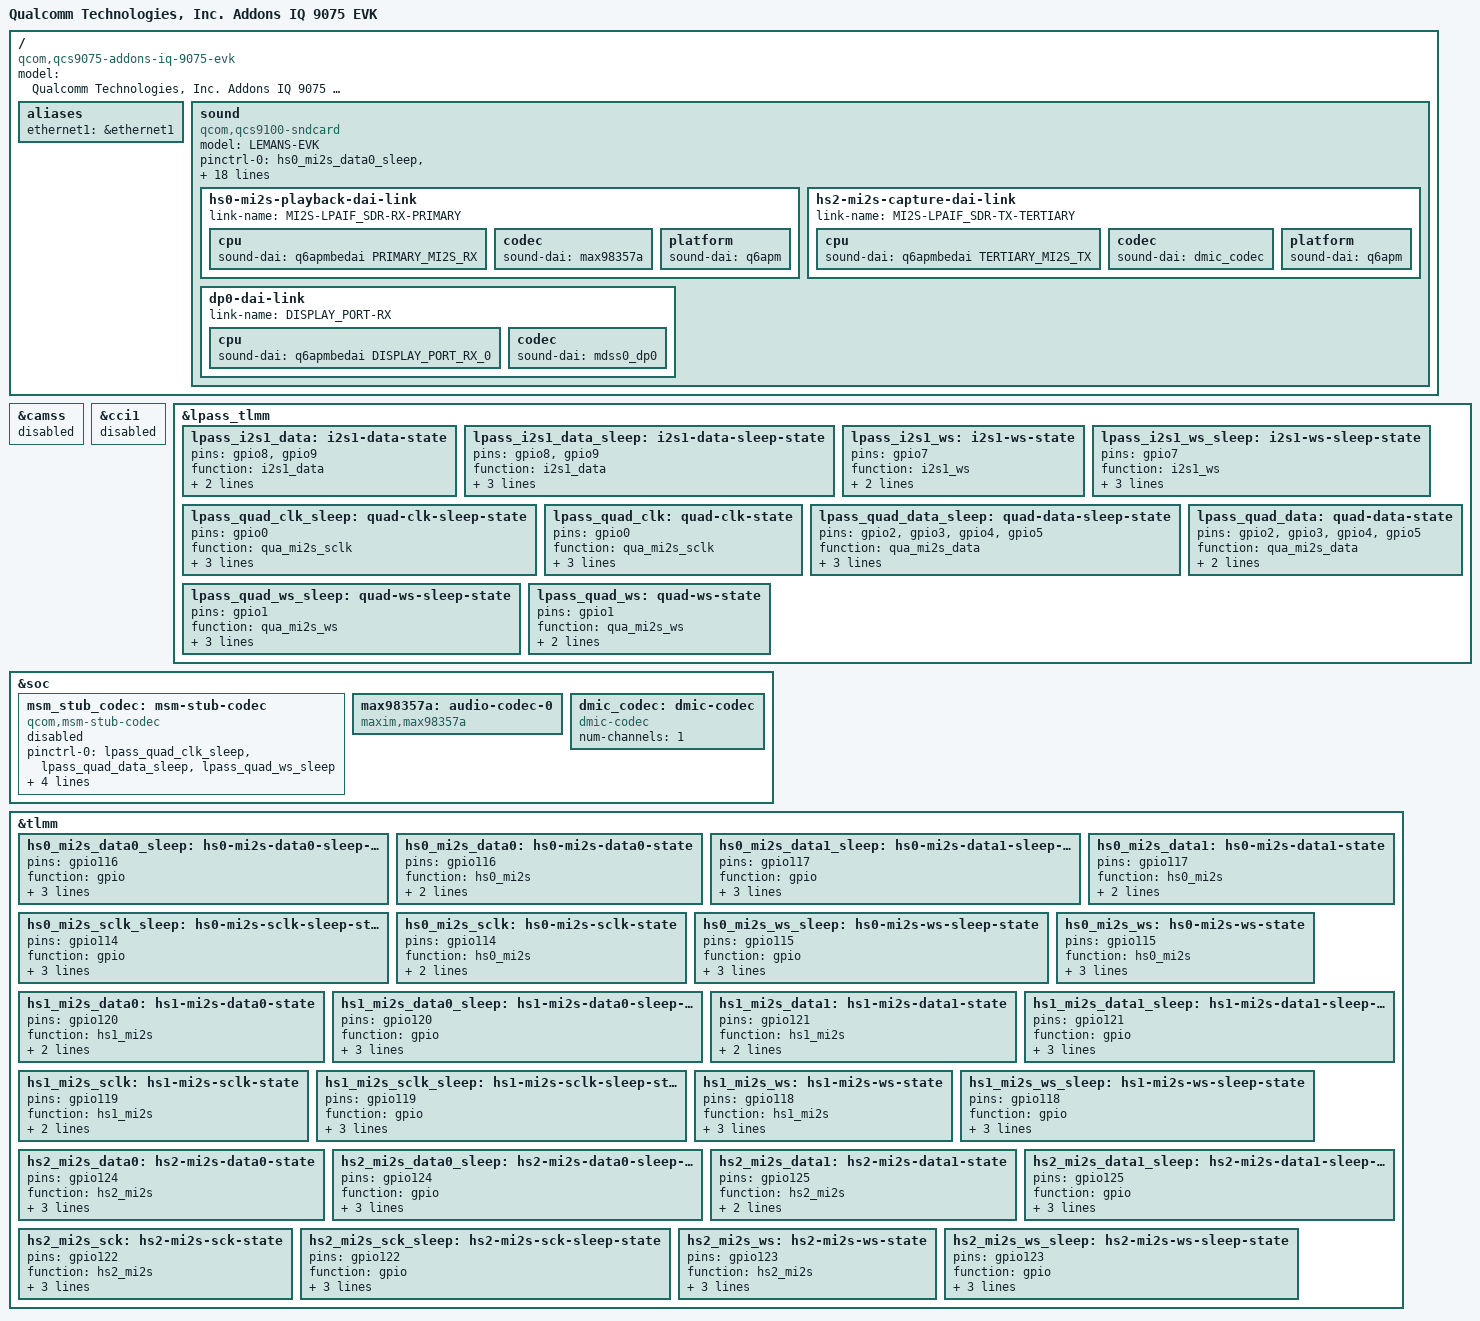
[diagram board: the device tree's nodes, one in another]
// SPDX-License-Identifier: BSD-3-Clause
/*
 * Copyright (c) 2024-2025, Qualcomm Innovation Center, Inc. All rights reserved.
 * Copyright (c) Qualcomm Technologies, Inc. and/or its subsidiaries.
 */
/dts-v1/;

#include "qcs9075-iq-9075-evk.dts"
#include "sa8775p-addons.dtsi"

/ {
	model = "Qualcomm Technologies, Inc. Addons IQ 9075 EVK";
	compatible = "qcom,qcs9075-addons-iq-9075-evk", "qcom,qcs9075", "qcom,sa8775p";

	aliases {
		ethernet1 = &ethernet1;
	};

	sound {
		compatible = "qcom,qcs9100-sndcard";
		model = "LEMANS-EVK";

		pinctrl-0 = <&hs0_mi2s_data0_sleep>,<&hs0_mi2s_data1_sleep>,<&hs0_mi2s_sclk_sleep>,
			    <&hs0_mi2s_ws_sleep>,<&hs1_mi2s_data0_sleep>,<&hs1_mi2s_data1_sleep>,
			    <&hs1_mi2s_sclk_sleep>,<&hs1_mi2s_ws_sleep>,<&hs2_mi2s_data0_sleep>,
			    <&hs2_mi2s_data1_sleep>, <&hs2_mi2s_sck_sleep>, <&hs2_mi2s_ws_sleep>;
		pinctrl-1 = <&hs1_mi2s_data0>, <&hs0_mi2s_data0>,
			    <&hs0_mi2s_sclk>, <&hs0_mi2s_data1>, <&hs0_mi2s_ws>,
			    <&hs1_mi2s_sclk>, <&hs1_mi2s_data1>, <&hs1_mi2s_ws>,
			    <&hs2_mi2s_data0>, <&hs2_mi2s_data1>, <&hs2_mi2s_sck>,
			    <&hs2_mi2s_ws>;
		pinctrl-2 = <&hs0_mi2s_data0_sleep>,<&hs0_mi2s_data1_sleep>,<&hs0_mi2s_sclk_sleep>,
                            <&hs0_mi2s_ws_sleep>,<&hs1_mi2s_data0_sleep>,<&hs1_mi2s_data1_sleep>,
                            <&hs1_mi2s_sclk_sleep>,<&hs1_mi2s_ws_sleep>,<&hs2_mi2s_data0_sleep>,
                            <&hs2_mi2s_data1_sleep>, <&hs2_mi2s_sck_sleep>, <&hs2_mi2s_ws_sleep>;

		pinctrl-names = "default", "mi2s_active", "mi2s_sleep";

		hs0-mi2s-playback-dai-link {
			link-name = "MI2S-LPAIF_SDR-RX-PRIMARY";

			cpu {
				sound-dai = <&q6apmbedai PRIMARY_MI2S_RX>;
			};

			codec {
				sound-dai = <&max98357a>;
			};

			platform {
				sound-dai = <&q6apm>;
			};
		};

		hs2-mi2s-capture-dai-link {
			link-name = "MI2S-LPAIF_SDR-TX-TERTIARY";

			cpu {
				sound-dai = <&q6apmbedai TERTIARY_MI2S_TX>;
			};

			codec {
				sound-dai = <&dmic_codec>;
			};

			platform {
				sound-dai = <&q6apm>;
			};
		};

		dp0-dai-link {
			link-name = "DISPLAY_PORT-RX";

			cpu {
				sound-dai = <&q6apmbedai DISPLAY_PORT_RX_0>;
			};

			codec {
				sound-dai = <&mdss0_dp0>;
			};
		};

	};
};

&camss {
	status = "disabled";
};

&cci1 {
	status = "disabled";
};

&lpass_tlmm {
	lpass_i2s1_data: i2s1-data-state {
			pins = "gpio8", "gpio9";
			function = "i2s1_data";
			drive-strength = <8>;
			bias-disable;
	};

	lpass_i2s1_data_sleep: i2s1-data-sleep-state {
			pins = "gpio8", "gpio9";
			function = "i2s1_data";
			drive-strength = <2>;
			bias-pull-down;
			input-enable;
	};

	lpass_i2s1_ws: i2s1-ws-state {
			pins = "gpio7";
			function = "i2s1_ws";
			drive-strength = <8>;
			output-high;
	};

	lpass_i2s1_ws_sleep: i2s1-ws-sleep-state {
			pins = "gpio7";
			function = "i2s1_ws";
			drive-strength = <2>;
			bias-pull-down;
			input-enable;
	};

	lpass_quad_clk_sleep: quad-clk-sleep-state {
			pins = "gpio0";
			function = "qua_mi2s_sclk";
			drive-strength = <2>;
			bias-pull-down;
			input-enable;
	};

	lpass_quad_clk: quad-clk-state {
			pins = "gpio0";
			function = "qua_mi2s_sclk";
			drive-strength = <8>;
			bias-disable;
			output-high;
	};

	lpass_quad_data_sleep: quad-data-sleep-state {
			pins = "gpio2", "gpio3", "gpio4", "gpio5";
			function = "qua_mi2s_data";
			drive-strength = <2>;
			bias-pull-down;
			input-enable;
	};

	lpass_quad_data: quad-data-state {
			pins = "gpio2", "gpio3", "gpio4", "gpio5";
			function = "qua_mi2s_data";
			drive-strength = <8>;
			bias-disable;
	};

	lpass_quad_ws_sleep: quad-ws-sleep-state {
			pins = "gpio1";
			function = "qua_mi2s_ws";
			drive-strength = <2>;
			bias-pull-down;
			input-enable;
	};

	lpass_quad_ws: quad-ws-state {
			pins = "gpio1";
			function = "qua_mi2s_ws";
			drive-strength = <8>;
			output-high;
	};
};

&soc {
	msm_stub_codec: msm-stub-codec {
		compatible = "qcom,msm-stub-codec";

		pinctrl-0 = <&lpass_quad_clk_sleep>, <&lpass_quad_data_sleep>,
			    <&lpass_quad_ws_sleep>;
		pinctrl-1 = <&lpass_quad_clk>, <&lpass_quad_data>, <&lpass_quad_ws>;
		pinctrl-2 = <&lpass_quad_clk_sleep>, <&lpass_quad_data_sleep>,
			    <&lpass_quad_ws_sleep>;
		pinctrl-names = "default", "mi2s_aud_active", "mi2s_aud_sleep";

		#sound-dai-cells = <1>;
		status = "disabled";
	};
	max98357a: audio-codec-0 {
		compatible = "maxim,max98357a";
		#sound-dai-cells = <0>;
	};

	dmic_codec: dmic-codec {
		compatible = "dmic-codec";
		#sound-dai-cells = <0>;
		num-channels = <1>;
	};
};

&tlmm {
	hs0_mi2s_data0_sleep: hs0-mi2s-data0-sleep-state {
		pins = "gpio116";
		function = "gpio";
		drive-strength = <2>;
		bias-pull-down;
		input-enable;
	};

	hs0_mi2s_data0: hs0-mi2s-data0-state {
		pins = "gpio116";
		function = "hs0_mi2s";
		drive-strength = <8>;
		bias-disable;
	};

	hs0_mi2s_data1_sleep: hs0-mi2s-data1-sleep-state {
		pins = "gpio117";
		function = "gpio";
		drive-strength = <2>;
		bias-pull-down;
		input-enable;
	};

	hs0_mi2s_data1: hs0-mi2s-data1-state {
		pins = "gpio117";
		function = "hs0_mi2s";
		drive-strength = <8>;
		bias-disable;
	};

	hs0_mi2s_sclk_sleep: hs0-mi2s-sclk-sleep-state {
		pins = "gpio114";
		function = "gpio";
		drive-strength = <2>;
		bias-pull-down;
		input-enable;
	};

	hs0_mi2s_sclk: hs0-mi2s-sclk-state {
		pins = "gpio114";
		function = "hs0_mi2s";
		drive-strength = <8>;
		bias-disable;
	};

	hs0_mi2s_ws_sleep: hs0-mi2s-ws-sleep-state {
		pins = "gpio115";
		function = "gpio";
		drive-strength = <2>;
		bias-pull-down;
		input-enable;
	};

	hs0_mi2s_ws: hs0-mi2s-ws-state {
		pins = "gpio115";
		function = "hs0_mi2s";
		drive-strength = <8>;
		bias-disable;
		output-high;
	};

	hs1_mi2s_data0: hs1-mi2s-data0-state {
		pins = "gpio120";
		function = "hs1_mi2s";
		drive-strength = <8>;
		bias-disable;
	};

	hs1_mi2s_data0_sleep: hs1-mi2s-data0-sleep-state {
		pins = "gpio120";
		function = "gpio";
		drive-strength = <2>;
		bias-pull-down;
		input-enable;
	};

	hs1_mi2s_data1: hs1-mi2s-data1-state {
		pins = "gpio121";
		function = "hs1_mi2s";
		drive-strength = <8>;
		bias-disable;
	};

	hs1_mi2s_data1_sleep: hs1-mi2s-data1-sleep-state {
		pins = "gpio121";
		function = "gpio";
		drive-strength = <2>;
		bias-pull-down;
		input-enable;
	};

	hs1_mi2s_sclk: hs1-mi2s-sclk-state {
		pins = "gpio119";
		function = "hs1_mi2s";
		drive-strength = <8>;
		bias-disable;
	};

	hs1_mi2s_sclk_sleep: hs1-mi2s-sclk-sleep-state {
		pins = "gpio119";
		function = "gpio";
		drive-strength = <2>;
		bias-pull-down;
		input-enable;
	};

	hs1_mi2s_ws: hs1-mi2s-ws-state {
		pins = "gpio118";
		function = "hs1_mi2s";
		drive-strength = <8>;
		bias-disable;
		output-high;
	};

	hs1_mi2s_ws_sleep: hs1-mi2s-ws-sleep-state {
		pins = "gpio118";
		function = "gpio";
		drive-strength = <2>;
		bias-pull-down;
		input-enable;
	};

	hs2_mi2s_data0: hs2-mi2s-data0-state {
		pins = "gpio124";
		function = "hs2_mi2s";
		drive-strength = <8>;
		input-enable;
		bias-disable;
	};

	hs2_mi2s_data0_sleep: hs2-mi2s-data0-sleep-state {
		pins = "gpio124";
		function = "gpio";
		drive-strength = <2>;
		bias-pull-down;
		input-enable;
	};

	hs2_mi2s_data1: hs2-mi2s-data1-state {
		pins = "gpio125";
		function = "hs2_mi2s";
		drive-strength = <8>;
		bias-disable;
	};

	hs2_mi2s_data1_sleep: hs2-mi2s-data1-sleep-state {
		pins = "gpio125";
		function = "gpio";
		drive-strength = <2>;
		bias-pull-down;
		input-enable;
	};

	hs2_mi2s_sck: hs2-mi2s-sck-state {
		pins = "gpio122";
		function = "hs2_mi2s";
		drive-strength = <8>;
		bias-disable;
		output-high;
	};

	hs2_mi2s_sck_sleep: hs2-mi2s-sck-sleep-state {
		pins = "gpio122";
		function = "gpio";
		drive-strength = <2>;
		bias-pull-down;
		input-enable;
	};

	hs2_mi2s_ws: hs2-mi2s-ws-state {
		pins = "gpio123";
		function = "hs2_mi2s";
		drive-strength = <8>;
		bias-disable;
		output-high;
	};

	hs2_mi2s_ws_sleep: hs2-mi2s-ws-sleep-state {
		pins = "gpio123";
		function = "gpio";
		drive-strength = <2>;
		bias-pull-down;
		input-enable;
	};

};
